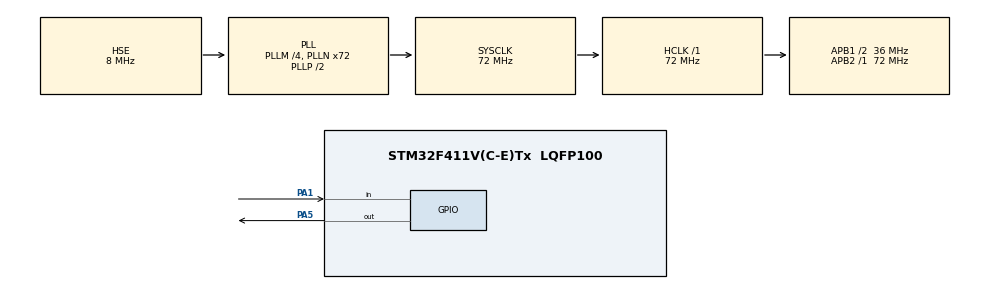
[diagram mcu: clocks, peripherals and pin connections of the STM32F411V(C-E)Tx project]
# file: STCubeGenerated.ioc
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Mcu.Family=STM32F4
Mcu.Name=STM32F411V(C-E)Tx
Mcu.Package=LQFP100
NVIC.PriorityGroup=NVIC_PRIORITYGROUP_4
NVIC.TIM2_IRQn=true\:0\:0\:false\:false\:true\:true\:true
PA1.GPIO_PuPd=GPIO_PULLUP
PA1.Signal=GPIO_Input
PA5.Signal=GPIO_Output
PH0\ -\ OSC_IN.Mode=HSE-External-Oscillator
PH0\ -\ OSC_IN.Signal=RCC_OSC_IN
PH1\ -\ OSC_OUT.Mode=HSE-External-Oscillator
PH1\ -\ OSC_OUT.Signal=RCC_OSC_OUT
ProjectManager.HeapSize=0x200
ProjectManager.StackSize=0x400
ProjectManager.TargetToolchain=MDK-ARM V5
RCC.48MHZClocksFreq_Value=36000000
RCC.AHBFreq_Value=72000000
RCC.APB1CLKDivider=RCC_HCLK_DIV2
RCC.APB1Freq_Value=36000000
RCC.APB1TimFreq_Value=72000000
RCC.APB2Freq_Value=72000000
RCC.APB2TimFreq_Value=72000000
RCC.CortexFreq_Value=72000000
RCC.HCLKFreq_Value=72000000
RCC.HSE_VALUE=8000000
RCC.HSI_VALUE=16000000
RCC.LSE_VALUE=32768
RCC.PLLM=4
RCC.PLLN=72
RCC.PLLSourceVirtual=RCC_PLLSOURCE_HSE
RCC.SYSCLKFreq_VALUE=72000000
RCC.SYSCLKSource=RCC_SYSCLKSOURCE_PLLCLK
RCC.VCOOutputFreq_Value=144000000
TIM2.Period=10000-1
TIM2.Prescaler=7200-1
VP_TIM2_VS_ClockSourceINT.Mode=Internal
board=custom

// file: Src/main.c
/* USER CODE BEGIN Header */
/**
  ******************************************************************************
  * @file           : main.c
  * @brief          : Main program body
  ******************************************************************************
  * @attention
  *
  * <h2><center>&copy; Copyright (c) 2022 STMicroelectronics.
  * All rights reserved.</center></h2>
  *
  * This software component is licensed by ST under BSD 3-Clause license,
  * the "License"; You may not use this file except in compliance with the
  * License. You may obtain a copy of the License at:
  *                        opensource.org/licenses/BSD-3-Clause
  *
  ******************************************************************************
  */
/* USER CODE END Header */

#include "main.h"
#include "tim.h"
#include "gpio.h"

void SystemClock_Config(void);

/* USER CODE BEGIN 0 */
/**
  * @brief  Period elapsed callback in non blocking mode
  * @param  htim: TIM handle
  * @retval None
  */
void HAL_TIM_PeriodElapsedCallback(TIM_HandleTypeDef *htim)
{
	static int cnt = 0;
	cnt++;
	if (htim->Instance == htim2.Instance)
	{
		HAL_GPIO_TogglePin(GPIOA, GPIO_PIN_5);
	}
}
/* USER CODE END 0 */

int main(void)
{

  /* MCU Configuration--------------------------------------------------------*/

  /* Reset of all peripherals, Initializes the Flash interface and the Systick. */
  HAL_Init();

  /* Configure the system clock */
  SystemClock_Config();

  /* Initialize all configured peripherals */
  MX_GPIO_Init();
  MX_TIM2_Init();
  /* USER CODE BEGIN 2 */
	HAL_TIM_Base_Start_IT(&htim2);

  /* USER CODE END 2 */

  /* Infinite loop */
  while (1)
  {

    /* USER CODE BEGIN 3 */
		HAL_Delay(1000);
  }
  /* USER CODE END 3 */
}

void SystemClock_Config(void)
{
  RCC_OscInitTypeDef RCC_OscInitStruct = {0};
  RCC_ClkInitTypeDef RCC_ClkInitStruct = {0};

  /** Configure the main internal regulator output voltage
  */
  __HAL_RCC_PWR_CLK_ENABLE();
  __HAL_PWR_VOLTAGESCALING_CONFIG(PWR_REGULATOR_VOLTAGE_SCALE1);
  /** Initializes the CPU, AHB and APB busses clocks
  */
  RCC_OscInitStruct.OscillatorType = RCC_OSCILLATORTYPE_HSE;
  RCC_OscInitStruct.HSEState = RCC_HSE_ON;
  RCC_OscInitStruct.PLL.PLLState = RCC_PLL_ON;
  RCC_OscInitStruct.PLL.PLLSource = RCC_PLLSOURCE_HSE;
  RCC_OscInitStruct.PLL.PLLM = 4;
  RCC_OscInitStruct.PLL.PLLN = 72;
  RCC_OscInitStruct.PLL.PLLP = RCC_PLLP_DIV2;
  RCC_OscInitStruct.PLL.PLLQ = 4;
  if (HAL_RCC_OscConfig(&RCC_OscInitStruct) != HAL_OK)
  {
    Error_Handler();
  }
  /** Initializes the CPU, AHB and APB busses clocks
  */
  RCC_ClkInitStruct.ClockType = RCC_CLOCKTYPE_HCLK|RCC_CLOCKTYPE_SYSCLK
                              |RCC_CLOCKTYPE_PCLK1|RCC_CLOCKTYPE_PCLK2;
  RCC_ClkInitStruct.SYSCLKSource = RCC_SYSCLKSOURCE_PLLCLK;
  RCC_ClkInitStruct.AHBCLKDivider = RCC_SYSCLK_DIV1;
  RCC_ClkInitStruct.APB1CLKDivider = RCC_HCLK_DIV2;
  RCC_ClkInitStruct.APB2CLKDivider = RCC_HCLK_DIV1;

  if (HAL_RCC_ClockConfig(&RCC_ClkInitStruct, FLASH_LATENCY_2) != HAL_OK)
  {
    Error_Handler();
  }
}

void Error_Handler(void)
{
}

/************************ (C) COPYRIGHT STMicroelectronics *****END OF FILE****/
